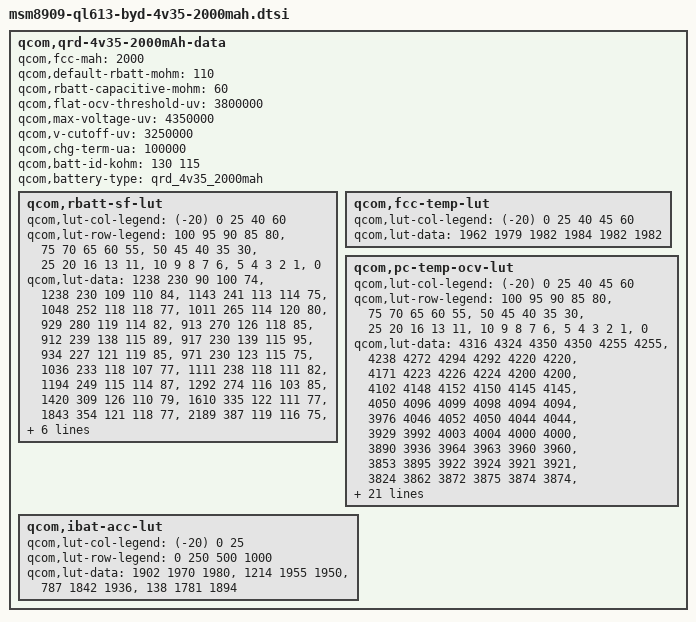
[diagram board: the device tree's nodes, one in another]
/* Copyright (c) 2013, The Linux Foundation. All rights reserved.
 *
 * This program is free software; you can redistribute it and/or modify
 * it under the terms of the GNU General Public License version 2 and
 * only version 2 as published by the Free Software Foundation.
 *
 * This program is distributed in the hope that it will be useful,
 * but WITHOUT ANY WARRANTY; without even the implied warranty of
 * MERCHANTABILITY or FITNESS FOR A PARTICULAR PURPOSE.  See the
 * GNU General Public License for more details.
 */
/* xiongzuan add battery information capacity and rbatt by 20150327 begin*/
qcom,qrd-4v35-2000mAh-data {
	qcom,fcc-mah = <2000>;
	qcom,default-rbatt-mohm = <110>;
	qcom,rbatt-capacitive-mohm = <60>;
	qcom,flat-ocv-threshold-uv = <3800000>;
	qcom,max-voltage-uv = <4350000>;
	qcom,v-cutoff-uv = <3250000>;
	qcom,chg-term-ua = <100000>;
	qcom,batt-id-kohm = <130 115>;
	qcom,battery-type = "qrd_4v35_2000mah";

	qcom,rbatt-sf-lut {
		qcom,lut-col-legend = <(-20) 0 25 40 60>;
		qcom,lut-row-legend = <100 95 90 85 80>,
				<75 70 65 60 55>,
				<50 45 40 35 30>,
				<25 20 16 13 11>,
				<10 9 8 7 6 >,
				<5 4 3 2 1>,
				<0>;
		qcom,lut-data = 
				<1238 230 90 100 74>,
				<1238 230 109 110 84>,
				<1143 241 113 114 75>,
				<1048 252 118 118 77>,
				<1011 265 114 120 80>,
				<929 280 119 114 82>,
				<913 270 126 118 85>,
				<912 239 138 115 89>,
				<917 230 139 115 95>,
				<934 227 121 119 85>,
				<971 230 123 115 75>,
				<1036 233 118 107 77>,
				<1111 238 118 111 82>,
				<1194 249 115 114 87>,
				<1292 274 116 103 85>,
				<1420 309 126 110 79>,
				<1610 335 122 111 77>,
				<1843 354 121 118 77>,
				<2189 387 119 116 75>,
				<2650 428 131 129 79>,
				<2770 449 135 135 80>,//10
				<2985 488 139 139 80>,
				<3418 524 133 137 83>,
				<3638 519 140 137 84>,
				<4565 587 144 137 84>,
				<6066 620 146 137 82>,
				<9075 605 151 137 84>,
				<8149 640 140 137 89>,
				<6298 631 142 133 100>,
				<7259 662 149 141 123>,
				<9451 925 257 243 207>;
	};

	qcom,fcc-temp-lut {
		qcom,lut-col-legend = <(-20) 0 25 40 45 60>;
		qcom,lut-data = <1962 1979 1982 1984 1982 1982>;
	};

	qcom,pc-temp-ocv-lut {
		qcom,lut-col-legend = <(-20) 0 25 40 45 60>;
		qcom,lut-row-legend = <100 95 90 85 80>,
				<75 70 65 60 55>,
				<50 45 40 35 30>,
				<25 20 16 13 11>,
				<10 9 8 7 6>,
				<5 4 3 2 1>,
				<0>;
		qcom,lut-data = 
 				<4316 4324 4350 4350 4255 4255>,//100
				<4238 4272 4294 4292 4220 4220>,
				<4171 4223 4226 4224 4200 4200>,//90
				<4102 4148 4152 4150 4145 4145>,
				<4050 4096 4099 4098 4094 4094>,//80
				<3976 4046 4052 4050 4044 4044>,
				<3929 3992 4003 4004 4000 4000>,//70
				<3890 3936 3964 3963 3960 3960>,
				<3853 3895 3922 3924 3921 3921>,//60
				<3824 3862 3872 3875 3874 3874>,
				<3804 3834 3845 3844 3838 3838>,//50
				<3786 3815 3823 3820 3814 3814>,
				<3769 3798 3802 3797 3794 3794>,//40
				<3752 3780 3782 3781 3779 3779>,
				<3737 3772 3765 3762 3761 3761>,//30
				<3724 3750 3744 3741 3737 3737>,
				<3710 3730 3723 3722 3715 3715>,//20
				<3698 3712 3700 3695 3688 3688>,
				<3685 3689 3682 3680 3676 3676>,//13
				<3668 3679 3677 3674 3668 3668>,
				<3660 3673 3673 3672 3660 3660>,//10
				<3645 3671 3670 3666 3658 3658>,
				<3628 3667 3665 3663 3656 3656>,
				<3606 3659 3657 3656 3651 3651>,
				<3576 3653 3652 3652 3638 3638>,
				<3535 3644 3637 3624 3604 3604>,
				<3478 3604 3589 3574 3552 3552>,
				<3398 3544 3522 3506 3490 3490>,
				<3360 3459 3432 3422 3398 3398>,
				<3340 3327 3390 3381 3354 3354>,
				<3300 3300 3300 3300 3300 3300>; 
	};
	qcom,ibat-acc-lut {
		qcom,lut-col-legend = <(-20) 0 25>;
		qcom,lut-row-legend = <0 250 500 1000>;
		qcom,lut-data = 
				<1902 1970 1980>,
				<1214 1955 1950>,
				<787 1842 1936>,
				<138 1781 1894>;
	};
};
/* xiongzuan add battery information capacity and rbatt by 20150807 end*/
